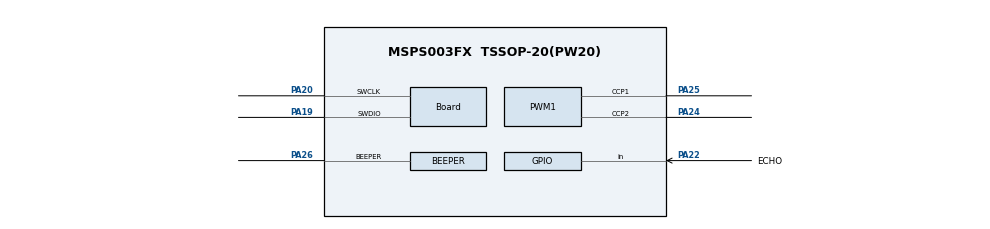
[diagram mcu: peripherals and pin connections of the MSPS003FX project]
/**
 * @cliArgs --device "MSPS003FX" --part "Default" --package "TSSOP-20(PW20)" --product "mspm0_sdk@2.03.00.07"
 * @versions {"tool":"1.22.0+3893"}
 */

/**
 * Import the modules used in this configuration.
 */
const ADC12         = scripting.addModule("/ti/driverlib/ADC12", {}, false);
const ADC121        = ADC12.addInstance();
const BEEPER        = scripting.addModule("/ti/driverlib/BEEPER");
const GPIO          = scripting.addModule("/ti/driverlib/GPIO", {}, false);
const GPIO1         = GPIO.addInstance();
const PWM           = scripting.addModule("/ti/driverlib/PWM", {}, false);
const PWM1          = PWM.addInstance();
const SYSCTL        = scripting.addModule("/ti/driverlib/SYSCTL");
const TIMER         = scripting.addModule("/ti/driverlib/TIMER", {}, false);
const TIMER1        = TIMER.addInstance();
const ProjectConfig = scripting.addModule("/ti/project_config/ProjectConfig");

/**
 * Write custom configuration values to the imported modules.
 */
ADC121.$name                      = "ADC12_0";
ADC121.sampClkDiv                 = "DL_ADC12_CLOCK_DIVIDE_8";
ADC121.powerDownMode              = "DL_ADC12_POWER_DOWN_MODE_MANUAL";
ADC121.sampleTime0                = "125 us";
ADC121.enabledInterrupts          = ["DL_ADC12_INTERRUPT_MEM0_RESULT_LOADED"];
ADC121.sampClkSrc                 = "DL_ADC12_CLOCK_ULPCLK";
ADC121.resolution                 = "DL_ADC12_SAMP_CONV_RES_12_BIT";
ADC121.peripheral.$assign         = "ADC0";
ADC121.peripheral.adcPin0.$assign = "PA27";
ADC121.adcPin0Config.$name        = "ti_driverlib_gpio_GPIOPinGeneric0";

BEEPER.beeperEnable                 = true;
BEEPER.beeperFreq                   = "8";
BEEPER.peripheral.$assign           = "SYSCTL";
BEEPER.peripheral.beeperPin.$assign = "PA26";

const Board                       = scripting.addModule("/ti/driverlib/Board", {}, false);
Board.peripheral.$assign          = "DEBUGSS";
Board.peripheral.swclkPin.$assign = "PA20";
Board.peripheral.swdioPin.$assign = "PA19";

GPIO1.$name                         = "GPIO_GRP_0";
GPIO1.associatedPins[0].$name       = "ECHO";
GPIO1.associatedPins[0].direction   = "INPUT";
GPIO1.associatedPins[0].interruptEn = true;
GPIO1.associatedPins[0].pubChanID   = 1;
GPIO1.associatedPins[0].polarity    = "RISE_FALL";
GPIO1.associatedPins[0].pin.$assign = "PA22";

PWM1.$name                              = "PWM_0";
PWM1.clockSource                        = "LFCLK";
PWM1.timerCount                         = 16384;
PWM1.timerStartTimer                    = true;
PWM1.ccIndex                            = [0,1,2];
PWM1.peripheral.ccp1Pin.$assign         = "PA25";
PWM1.peripheral.ccp2Pin.$assign         = "PA24";
PWM1.ccp1PinConfig.$name                = "ti_driverlib_gpio_GPIOPinGeneric5";
PWM1.ccp1PinConfig.direction            = scripting.forceWrite("OUTPUT");
PWM1.ccp1PinConfig.hideOutputInversion  = scripting.forceWrite(false);
PWM1.ccp1PinConfig.onlyInternalResistor = scripting.forceWrite(false);
PWM1.ccp1PinConfig.passedPeripheralType = scripting.forceWrite("Digital");
PWM1.PWM_CHANNEL_2.$name                = "ti_driverlib_pwm_PWMTimerCC0";
PWM1.PWM_CHANNEL_2.dutyCycle            = 50;
PWM1.ccp2PinConfig.$name                = "ti_driverlib_gpio_GPIOPinGeneric1";
PWM1.PWM_CHANNEL_0.$name                = "ti_driverlib_pwm_PWMTimerCC1";
PWM1.ccp0PinConfig.$name                = "ti_driverlib_gpio_GPIOPinGeneric2";
PWM1.PWM_CHANNEL_1.$name                = "ti_driverlib_pwm_PWMTimerCC2";

SYSCTL.MFCLKEn            = true;
SYSCTL.peripheral.$assign = "SYSCTL";

TIMER1.$name              = "TIMER_0";
TIMER1.timerClkPrescale   = 256;
TIMER1.interrupts         = ["ZERO"];
TIMER1.timerPeriod        = "500 ms";
TIMER1.timerMode          = "PERIODIC_UP";
TIMER1.peripheral.$assign = "TIMA0";

ProjectConfig.migrationCondition = true;

/**
 * Pinmux solution for unlocked pins/peripherals. This ensures that minor changes to the automatic solver in a future
 * version of the tool will not impact the pinmux you originally saw.  These lines can be completely deleted in order to
 * re-solve from scratch.
 */
PWM1.peripheral.$suggestSolution         = "TIMG14";
PWM1.peripheral.ccp0Pin.$suggestSolution = "PA23";
